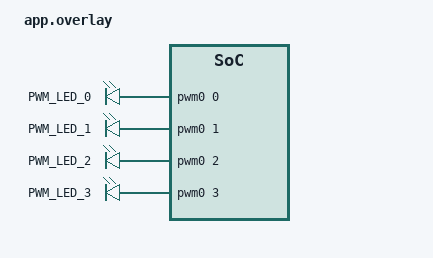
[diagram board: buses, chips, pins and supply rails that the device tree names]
/{
	pwmleds {
		compatible = "pwm-leds";
		pwm_led0: pwm_led_0 {
			pwms = <&pwm0 0 PWM_MSEC(20) PWM_POLARITY_INVERTED>;
			label = "PWM_LED_0";
		};
		pwm_led1: pwm_led_1 {
			pwms = <&pwm0 1 PWM_MSEC(20) PWM_POLARITY_INVERTED>;
			label = "PWM_LED_1";
		};
		pwm_led2: pwm_led_2 {
			pwms = <&pwm0 2 PWM_MSEC(20) PWM_POLARITY_INVERTED>;
			label = "PWM_LED_2";
		};
		pwm_led3: pwm_led_3 {
			pwms = <&pwm0 3 PWM_MSEC(20) PWM_POLARITY_INVERTED>;
			label = "PWM_LED_3";
		};
	};
	aliases {
		pwm-led0 = &pwm_led0;
		pwm-led1 = &pwm_led1;
		pwm-led2 = &pwm_led2;
		pwm-led3 = &pwm_led3;
	};

};

&pwm0 {
	pinctrl-0 = <&pwm0_default_alt>;
	pinctrl-1 = <&pwm0_sleep_alt>;
	pinctrl-names = "default", "sleep";
};

&pinctrl {
	pwm0_default_alt: pwm0_default_alt {
		group1 {
			psels = <NRF_PSEL(PWM_OUT0, 0, 0xd)>,
					<NRF_PSEL(PWM_OUT1, 0, 0xe)>,
					<NRF_PSEL(PWM_OUT2, 0, 0xf)>,
					<NRF_PSEL(PWM_OUT3, 0, 0x10)>;
			nordic,invert;
		};
	};

	pwm0_sleep_alt: pwm0_sleep_alt {
		group1 {
			psels = <NRF_PSEL(PWM_OUT0, 0, 0xd)>,
					<NRF_PSEL(PWM_OUT1, 0, 0xe)>,
					<NRF_PSEL(PWM_OUT2, 0, 0xf)>,
					<NRF_PSEL(PWM_OUT3, 0, 0x10)>;
			low-power-enable;
		};
	};
};
